AUTOSAR XML (schema 4-0-3)
package /ComponentTypes
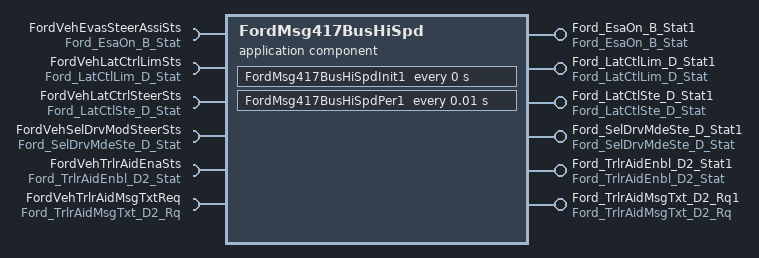
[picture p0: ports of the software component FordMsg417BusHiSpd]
  application sw component type FordMsg417BusHiSpd
    6 x provide port:
      Ford_EsaOn_B_Stat1: nonqueued-sender-com-spec{data-element=Ford_EsaOn_B_Stat, init-value=1}, provided-interface=Ford_EsaOn_B_Stat
      Ford_LatCtlLim_D_Stat1: nonqueued-sender-com-spec{data-element=Ford_LatCtlLim_D_Stat, init-value=0}, provided-interface=Ford_LatCtlLim_D_Stat
      Ford_LatCtlSte_D_Stat1: nonqueued-sender-com-spec{data-element=Ford_LatCtlSte_D_Stat, init-value=0}, provided-interface=Ford_LatCtlSte_D_Stat
      Ford_SelDrvMdeSte_D_Stat1: nonqueued-sender-com-spec{data-element=Ford_SelDrvMdeSte_D_Stat, init-value=0}, provided-interface=Ford_SelDrvMdeSte_D_Stat
      Ford_TrlrAidEnbl_D2_Stat1: nonqueued-sender-com-spec{data-element=Ford_TrlrAidEnbl_D2_Stat, init-value=0}, provided-interface=Ford_TrlrAidEnbl_D2_Stat
      Ford_TrlrAidMsgTxt_D2_Rq1: nonqueued-sender-com-spec{data-element=Ford_TrlrAidMsgTxt_D2_Rq, init-value=0}, provided-interface=Ford_TrlrAidMsgTxt_D2_Rq
    6 x require port:
      FordVehEvasSteerAssiSts: nonqueued-receiver-com-spec{data-element=Ford_EsaOn_B_Stat, filter=data-filter-type=ALWAYS, init-value=1}, required-interface=Ford_EsaOn_B_Stat
      FordVehLatCtrlLimSts: nonqueued-receiver-com-spec{data-element=Ford_LatCtlLim_D_Stat, filter=data-filter-type=ALWAYS, init-value=0}, required-interface=Ford_LatCtlLim_D_Stat
      FordVehLatCtrlSteerSts: nonqueued-receiver-com-spec{data-element=Ford_LatCtlSte_D_Stat, filter=data-filter-type=ALWAYS, init-value=0}, required-interface=Ford_LatCtlSte_D_Stat
      FordVehSelDrvModSteerSts: nonqueued-receiver-com-spec{data-element=Ford_SelDrvMdeSte_D_Stat, filter=data-filter-type=ALWAYS, init-value=0}, required-interface=Ford_SelDrvMdeSte_D_Stat
      FordVehTrlrAidEnaSts: nonqueued-receiver-com-spec{data-element=Ford_TrlrAidEnbl_D2_Stat, filter=data-filter-type=ALWAYS, init-value=0}, required-interface=Ford_TrlrAidEnbl_D2_Stat
      FordVehTrlrAidMsgTxtReq: nonqueued-receiver-com-spec{data-element=Ford_TrlrAidMsgTxt_D2_Rq, filter=data-filter-type=ALWAYS, init-value=0}, required-interface=Ford_TrlrAidMsgTxt_D2_Rq
    behavior FordMsg417BusHiSpd_InternalBehavior
      timing event FordMsg417BusHiSpd_InitEvent: start-on-event=FordMsg417BusHiSpdInit1, period=0
      timing event TMT_FordMsg417BusHiSpdPer1: start-on-event=FordMsg417BusHiSpdPer1, period=0.01
      port-api-options:
        enable-take-address=false, indirect-api=false, port=Ford_EsaOn_B_Stat1
        enable-take-address=false, indirect-api=false, port=FordVehEvasSteerAssiSts
      runnable FordMsg417BusHiSpdInit1
      runnable FordMsg417BusHiSpdPer1
        data-receive-point-by-arguments:
          6 x access:
            REC_FordVehEvasSteerAssiSts_Ford_EsaOn_B_Stat: accessed-variable=FordVehEvasSteerAssiSts.Ford_EsaOn_B_Stat
            REC_FordVehLatCtrlLimSts_Ford_LatCtlLim_D_Stat: accessed-variable=FordVehLatCtrlLimSts.Ford_LatCtlLim_D_Stat
            REC_FordVehLatCtrlSteerSts_Ford_LatCtlSte_D_Stat: accessed-variable=FordVehLatCtrlSteerSts.Ford_LatCtlSte_D_Stat
            REC_FordVehSelDrvModSteerSts_Ford_SelDrvMdeSte_D_Stat: accessed-variable=FordVehSelDrvModSteerSts.Ford_SelDrvMdeSte_D_Stat
            REC_FordVehTrlrAidEnaSts_Ford_TrlrAidEnbl_D2_Stat: accessed-variable=FordVehTrlrAidEnaSts.Ford_TrlrAidEnbl_D2_Stat
            REC_FordVehTrlrAidMsgTxtReq_Ford_TrlrAidMsgTxt_D2_Rq: accessed-variable=FordVehTrlrAidMsgTxtReq.Ford_TrlrAidMsgTxt_D2_Rq
        data-send-points:
          6 x access:
            SEND_Ford_EsaOn_B_Stat1_Ford_EsaOn_B_Stat: accessed-variable=Ford_EsaOn_B_Stat1.Ford_EsaOn_B_Stat
            SEND_Ford_LatCtlLim_D_Stat1_Ford_LatCtlLim_D_Stat: accessed-variable=Ford_LatCtlLim_D_Stat1.Ford_LatCtlLim_D_Stat
            SEND_Ford_LatCtlSte_D_Stat1_Ford_LatCtlSte_D_Stat: accessed-variable=Ford_LatCtlSte_D_Stat1.Ford_LatCtlSte_D_Stat
            SEND_Ford_SelDrvMdeSte_D_Stat1_Ford_SelDrvMdeSte_D_Stat: accessed-variable=Ford_SelDrvMdeSte_D_Stat1.Ford_SelDrvMdeSte_D_Stat
            SEND_Ford_TrlrAidEnbl_D2_Stat1_Ford_TrlrAidEnbl_D2_Stat: accessed-variable=Ford_TrlrAidEnbl_D2_Stat1.Ford_TrlrAidEnbl_D2_Stat
            SEND_Ford_TrlrAidMsgTxt_D2_Rq1_Ford_TrlrAidMsgTxt_D2_Rq: accessed-variable=Ford_TrlrAidMsgTxt_D2_Rq1.Ford_TrlrAidMsgTxt_D2_Rq
  swc implementation FordMsg417BusHiSpd_Implementation: behavior=FordMsg417BusHiSpd_InternalBehavior
    code-descriptors:
      code Default: artifact-descriptors=autosar-engineering-object={short-label=Default, category=SWSRC}
